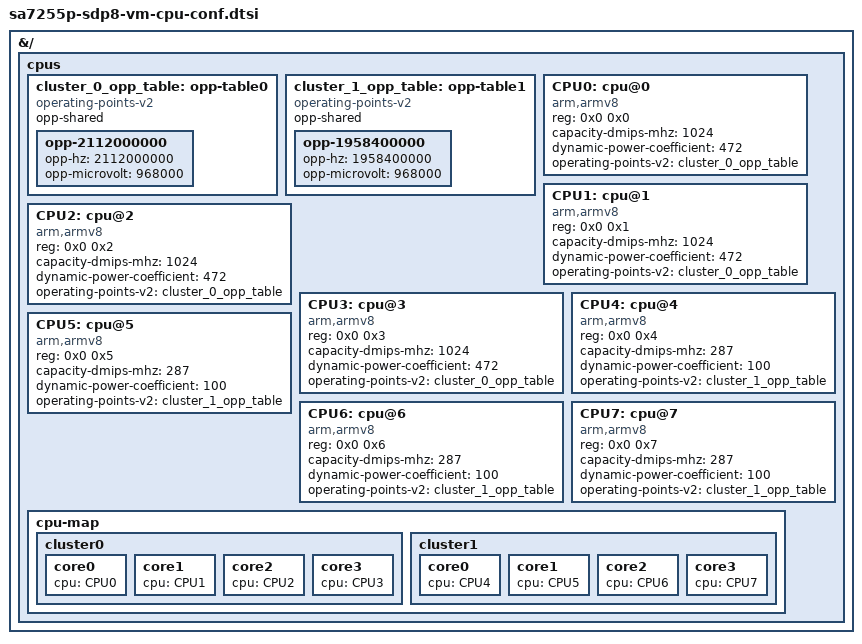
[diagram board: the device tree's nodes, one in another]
// SPDX-License-Identifier: BSD-3-Clause
/*
 * Copyright (c) Qualcomm Technologies, Inc. and/or its subsidiaries.
 */

&{/} {
	cpus {
		#address-cells = <2>;
		#size-cells = <0>;

		cluster_0_opp_table: opp-table0 {
			compatible = "operating-points-v2";
			opp-shared;

			opp-2112000000 {
				opp-hz = /bits/ 64 <2112000000>;
				opp-microvolt = <968000>;
			};
		};

		cluster_1_opp_table: opp-table1 {
			compatible = "operating-points-v2";
			opp-shared;

			opp-1958400000 {
				opp-hz = /bits/ 64 <1958400000>;
				opp-microvolt = <968000>;
			};
		};

		CPU0: cpu@0 {
			device_type = "cpu";
			compatible = "arm,armv8";
			reg = <0x0 0x0>;
			capacity-dmips-mhz = <1024>;
			dynamic-power-coefficient = <472>;
			operating-points-v2 = <&cluster_0_opp_table>;
		};

		CPU1: cpu@1 {
			device_type = "cpu";
			compatible = "arm,armv8";
			reg = <0x0 0x1>;
			capacity-dmips-mhz = <1024>;
			dynamic-power-coefficient = <472>;
			operating-points-v2 = <&cluster_0_opp_table>;
		};

		CPU2: cpu@2 {
			device_type = "cpu";
			compatible = "arm,armv8";
			reg = <0x0 0x2>;
			capacity-dmips-mhz = <1024>;
			dynamic-power-coefficient = <472>;
			operating-points-v2 = <&cluster_0_opp_table>;
		};

		CPU3: cpu@3 {
			device_type = "cpu";
			compatible = "arm,armv8";
			reg = <0x0 0x3>;
			capacity-dmips-mhz = <1024>;
			dynamic-power-coefficient = <472>;
			operating-points-v2 = <&cluster_0_opp_table>;
		};

		CPU4: cpu@4 {
			device_type = "cpu";
			compatible = "arm,armv8";
			reg = <0x0 0x4>;
			capacity-dmips-mhz = <287>;
			dynamic-power-coefficient = <100>;
			operating-points-v2 = <&cluster_1_opp_table>;
		};

		CPU5: cpu@5 {
			device_type = "cpu";
			compatible = "arm,armv8";
			reg = <0x0 0x5>;
			capacity-dmips-mhz = <287>;
			dynamic-power-coefficient = <100>;
			operating-points-v2 = <&cluster_1_opp_table>;
		};

		CPU6: cpu@6 {
			device_type = "cpu";
			compatible = "arm,armv8";
			reg = <0x0 0x6>;
			capacity-dmips-mhz = <287>;
			dynamic-power-coefficient = <100>;
			operating-points-v2 = <&cluster_1_opp_table>;
		};

		CPU7: cpu@7 {
			device_type = "cpu";
			compatible = "arm,armv8";
			reg = <0x0 0x7>;
			capacity-dmips-mhz = <287>;
			dynamic-power-coefficient = <100>;
			operating-points-v2 = <&cluster_1_opp_table>;
		};

		cpu-map {
			cluster0 {
				core0 {
					cpu = <&CPU0>;
				};

				core1 {
					cpu = <&CPU1>;
				};

				core2 {
					cpu = <&CPU2>;
				};

				core3 {
					cpu = <&CPU3>;
				};
			};

			cluster1 {
				core0 {
					cpu = <&CPU4>;
				};

				core1 {
					cpu = <&CPU5>;
				};

				core2 {
					cpu = <&CPU6>;
				};

				core3 {
					cpu = <&CPU7>;
				};
			};
		};
	};
};
